# alb32r003x register map
Vendor: ALB; Series: ALB RT SoC
CPU: ALB XF, little endian
Registers are 32-bit, access not given, reset 0x0 unless marked. A register's access mark holds for its fields unless they carry their own. Offsets are from the block's base; [hi:lo] are bit positions; {n}, {i} and the like mark numbered series; 'fields as' and 'values as' point back to an identical list.

## EPWM1
Base 0x21000000
Same registers: EPWM2 0x21000400, EPWM3 0x21000800, EPWM4 0x21000C00, EPWM5 0x21001000, EPWM6 0x21001400, EPWM7 0x21001800, EPWM8 0x21001C00
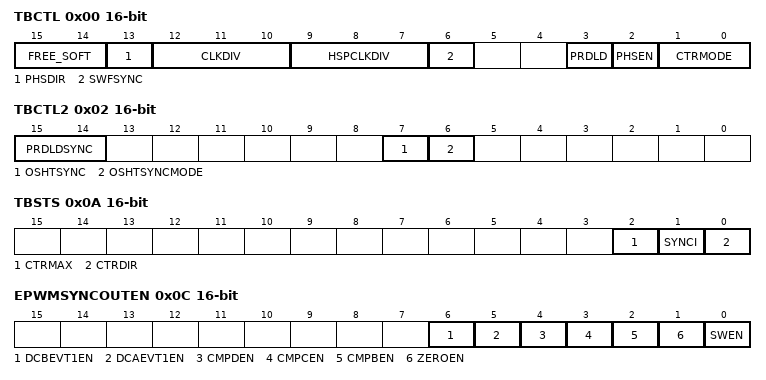
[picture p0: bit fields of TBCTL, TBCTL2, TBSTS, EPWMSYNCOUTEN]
0x00 TBCTL 16-bit
  [15:14] FREE_SOFT — 该寄存器未使用
  [13] PHSDIR — Phase Direction Bit
  [12:10] CLKDIV — Time Base Clock Pre-Scale Bits
  [9:7] HSPCLKDIV — High Speed Time Base Clock Pre-Scale Bits
  [6] SWFSYNC — Software Forced Sync Pulse
  [3] PRDLD — Active Period Reg Load from Shadow Select
  [2] PHSEN — Counter Reg Load from Phase Reg Enable
  [1:0] CTRMODE — Counter Mode
0x02 TBCTL2 16-bit
  [15:14] PRDLDSYNC — Shadow to Active Period Register Load on SYNC event
  [7] OSHTSYNC — Oneshot sync bit
  [6] OSHTSYNCMODE — Oneshot sync enable bit
0x08 TBCTR 16-bit
  [15:0] TBCTR — Time Base Counter Register
0x0A TBSTS 16-bit
  [2] CTRMAX — Time-Base Counter Max Latched Status Bit
  [1] SYNCI — Input Synchronization Latched Status Bit
  [0] CTRDIR — Time Base Counter Direction Status Bit
0x0C EPWMSYNCOUTEN 16-bit
  [6] DCBEVT1EN — This bit enables the DCBEVT1.sync event to set the EPWMxSYNCO
  [5] DCAEVT1EN — This bit enables the DCAEVT1.sync event to set the
  [4] CMPDEN — This bit enables the TBCTR = CMPD
  [3] CMPCEN — This bit enables the TBCTR = CMPC
  [2] CMPBEN — This bit enables the TBCTR = CMPB event to set the
  [1] ZEROEN — This bit enables the TBCTR = 0x0000 event to set the
  [0] SWEN — This bit enables the TBCTL.SWFSYNC bit to set the EPWMxSYNCO
0x0E TBCTL3 16-bit
  [0] OSSFRCEN — This bit determines which bit sets the EPWMxSYNCOUT One Shot
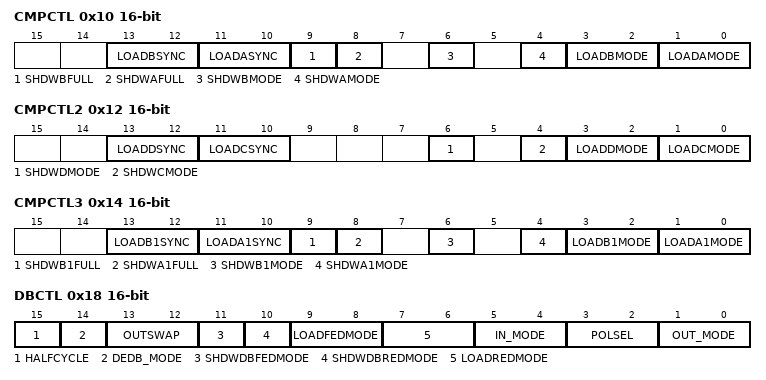
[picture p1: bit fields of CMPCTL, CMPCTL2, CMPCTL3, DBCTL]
0x10 CMPCTL 16-bit
  [13:12] LOADBSYNC — Shadow to Active CMPB Register Load on SYNC event
  [11:10] LOADASYNC — Shadow to Active CMPA Register Load on SYNC event
  [9] SHDWBFULL — Counter-compare B (CMPB) Shadow Register Full Status Flag
  [8] SHDWAFULL — Counter-compare A (CMPA) Shadow Register Full Status Flag
  [6] SHDWBMODE — Counter-compare B (CMPB) Register Operating Mode
  [4] SHDWAMODE — Counter-compare A (CMPA) Register Operating Mode
  [3:2] LOADBMODE — Active Counter-Compare B (CMPB) Load From Shadow Select
  [1:0] LOADAMODE — Active Counter-Compare A (CMPA) Load From Shadow Select Mode
0x12 CMPCTL2 16-bit
  [13:12] LOADDSYNC — Shadow to Active CMPD Register Load on SYNC event
  [11:10] LOADCSYNC — Shadow to Active CMPC Register Load on SYNC event
  [6] SHDWDMODE — Counter-Compare D Register Operating Mode
  [4] SHDWCMODE — Counter-Compare C Register Operating Mode
  [3:2] LOADDMODE — Active Counter-Compare D (CMPD) Load from Shadow Select Mode
  [1:0] LOADCMODE — Active Counter-Compare C (CMPC) Load from Shadow Select Mode
0x14 CMPCTL3 16-bit
  [13:12] LOADB1SYNC — Shadow to Active CMPB1 Register Load on SYNC event
  [11:10] LOADA1SYNC — Shadow to Active CMPA1 Register Load on SYNC event
  [9] SHDWB1FULL — Counter-compare B1 (CMPB1) Shadow Register Full Status Flag
  [8] SHDWA1FULL — Counter-compare A1 (CMPA1) Shadow Register Full Status Flag
  [6] SHDWB1MODE — Counter-compare B1 (CMPB1) Register Operating Mode
  [4] SHDWA1MODE — Counter-compare A1 (CMPA1) Register Operating Mode
  [3:2] LOADB1MODE — Active Counter-Compare B1 (CMPB1) Load From Shadow Select
  [1:0] LOADA1MODE — Active Counter-Compare A1 (CMPA1) Load From Shadow Select Mode
0x18 DBCTL 16-bit
  [15] HALFCYCLE — 该寄存器未使用
  [14] DEDB_MODE — Dead Band Dual-Edge B Mode Control (S8 switch)
  [13:12] OUTSWAP — Dead Band Output Swap Control
  [11] SHDWDBFEDMODE — FED Dead-Band Load Mode
  [10] SHDWDBREDMODE — RED Dead-Band Load Mode
  [9:8] LOADFEDMODE — Active DBFED Load from Shadow Select Mode
  [7:6] LOADREDMODE — Active DBRED Load from Shadow Select Mode
  [5:4] IN_MODE — Dead-Band Input Mode Control
  [3:2] POLSEL — Polarity Select Control
  [1:0] OUT_MODE — Dead-Band Output Mode Control
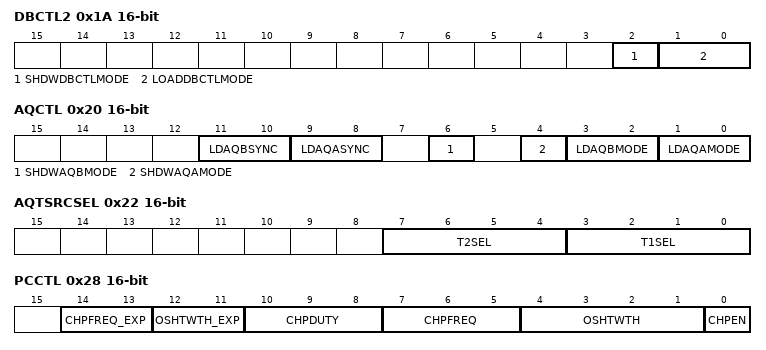
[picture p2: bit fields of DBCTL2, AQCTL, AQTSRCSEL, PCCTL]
0x1A DBCTL2 16-bit
  [2] SHDWDBCTLMODE — DBCTL Load Mode
  [1:0] LOADDBCTLMODE — Active DBCTL Load from Shadow Select Mode
0x20 AQCTL 16-bit
  [11:10] LDAQBSYNC — Shadow to Active AQCTLB Register Load on SYNC event
  [9:8] LDAQASYNC — Shadow to Active AQCTLA Register Load on SYNC event
  [6] SHDWAQBMODE — Action Qualifier B Register operating mode
  [4] SHDWAQAMODE — Action Qualifier A Register operating mode
  [3:2] LDAQBMODE — Active Action Qualifier B Load from Shadow Select Mode
  [1:0] LDAQAMODE — Active Action Qualifier A Load from Shadow Select Mode
0x22 AQTSRCSEL 16-bit
  [7:4] T2SEL — T2 Event Source Select Bits
  [3:0] T1SEL — T1 Event Source Select Bits
0x28 PCCTL 16-bit
  [14:13] CHPFREQ_EXP — Chopping Clock Frequency EXP
  [12:11] OSHTWTH_EXP — One-Shot Pulse Width EXP
  [10:8] CHPDUTY — Chopping Clock Duty Cycle
  [7:5] CHPFREQ — Chopping Clock Frequency
  [4:1] OSHTWTH — One-Shot Pulse Width
  [0] CHPEN — PWM-Chopping Enable
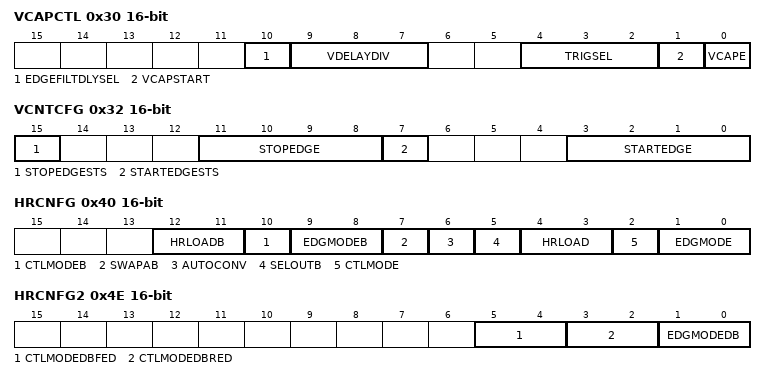
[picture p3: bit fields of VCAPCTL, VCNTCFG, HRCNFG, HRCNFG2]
0x30 VCAPCTL 16-bit
  [10] EDGEFILTDLYSEL — Valley Switching Mode Delay Selection
  [9:7] VDELAYDIV — Valley Delay Mode Divide Enable
  [4:2] TRIGSEL — Status of Numbered of Captured Events
  [1] VCAPSTART — Valley Capture Start
  [0] VCAPE — Valley Capture Enable/Disable
0x32 VCNTCFG 16-bit
  [15] STOPEDGESTS — Stop Edge Status Bit
  [11:8] STOPEDGE — Counter Stop Edge Selection
  [7] STARTEDGESTS — Start Edge Status Bit
  [3:0] STARTEDGE — Counter Start Edge Selection
0x40 HRCNFG 16-bit
  [12:11] HRLOADB — Shadow Mode Bit
  [10] CTLMODEB — 该寄存器未使用
  [9:8] EDGMODEB — 该寄存器未使用
  [7] SWAPAB — 该寄存器未使用
  [6] AUTOCONV — 该寄存器未使用
  [5] SELOUTB — 该寄存器未使用
  [4:3] HRLOAD — Shadow Mode Bit
  [2] CTLMODE — 该寄存器未使用
  [1:0] EDGMODE — 该寄存器未使用
0x42 HRPWR 16-bit
  [15] CALPWRON — 该寄存器未使用
0x4C HRMSTEP 16-bit
  [7:0] HRMSTEP — 该寄存器未使用
0x4E HRCNFG2 16-bit
  [5:4] CTLMODEDBFED — Shadow Mode Bit - selection should match
  [3:2] CTLMODEDBRED — Shadow Mode Bit - selection should match
  [1:0] EDGMODEDB — 该寄存器未使用
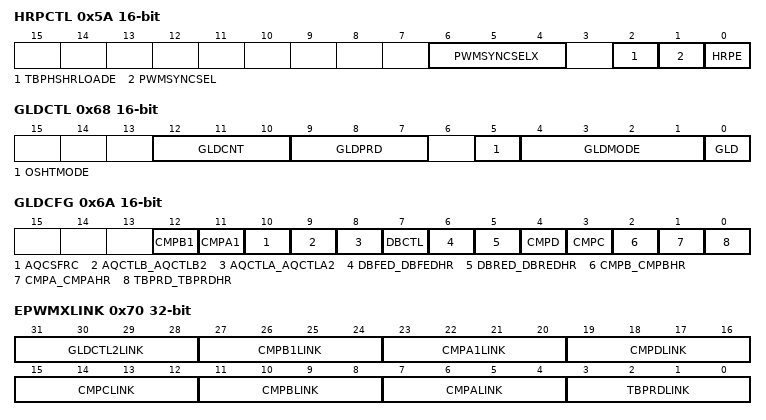
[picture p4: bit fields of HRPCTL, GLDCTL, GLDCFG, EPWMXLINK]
0x5A HRPCTL 16-bit
  [6:4] PWMSYNCSELX — Extended selection bits for EPWMSYNCPER
  [2] TBPHSHRLOADE — TBPHSHR Load Enable
  [1] PWMSYNCSEL — PWMSYNC Source Select Bit: This bit selects the source for the
  [0] HRPE — 该寄存器未使用
0x5C TRREM 16-bit
  [10:0] TRREM — 该寄存器未使用
0x68 GLDCTL 16-bit
  [12:10] GLDCNT — Global Load Strobe Counter Register
  [9:7] GLDPRD — Global Load Strobe Period Select Register
  [5] OSHTMODE — One Shot Load Mode Control Bit
  [4:1] GLDMODE — Global Load Pulse selection for Shadow to Active Mode Reloads
  [0] GLD — Global Shadow to Active Load Event Control
0x6A GLDCFG 16-bit
  [12] CMPB1 — CMPB1 Link Bits
  [11] CMPA1 — CMPA1 Link Bits
  [10] AQCSFRC — Global load event configuration for AQCSFRC
  [9] AQCTLB_AQCTLB2 — Global load event configuration for AQCTLB AQCTLB2
  [8] AQCTLA_AQCTLA2 — Global load event configuration for AQCTLA AQCTLA2
  [7] DBCTL — Global load event configuration for DBCTL
  [6] DBFED_DBFEDHR — Global load event configuration for DBFED DBFEDHR
  [5] DBRED_DBREDHR — Global load event configuration for DBRED DBREDHR
  [4] CMPD — Global load event configuration for CMPD
  [3] CMPC — Global load event configuration for CMPC
  [2] CMPB_CMPBHR — Global load event configuration for CMPB CMPBHR
  [1] CMPA_CMPAHR — Global load event configuration for CMPA CMPAHR
  [0] TBPRD_TBPRDHR — Global load event configuration for TBPRD TBPRDHR
0x70 EPWMXLINK
  [31:28] GLDCTL2LINK — GLDCTL2 Link Bits
  [27:24] CMPB1LINK — CMPB1 Link Bits
  [23:20] CMPA1LINK — CMPA1 Link Bits
  [19:16] CMPDLINK — CMPD Link Bits
  [15:12] CMPCLINK — CMPC Link Bits
  [11:8] CMPBLINK — CMPB CMPBHR Link Bits
  [7:4] CMPALINK — CMPA CMPAHR Link Bits
  [3:0] TBPRDLINK — TBPRD TBPRDHR Link Bits
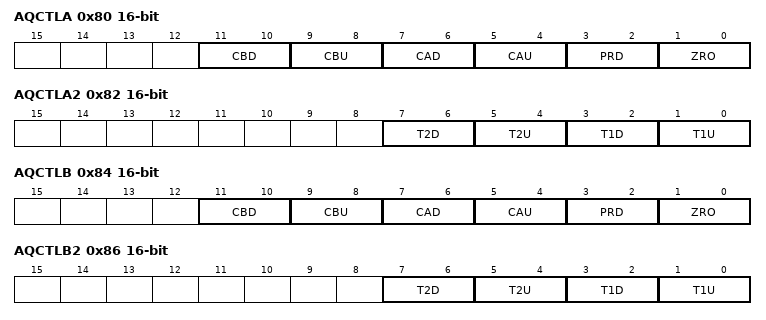
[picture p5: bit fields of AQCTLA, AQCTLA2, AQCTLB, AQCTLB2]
0x80 AQCTLA 16-bit
  [11:10] CBD — Action When TBCTR = CMPB on Down Count
  [9:8] CBU — Action When TBCTR = CMPB on Up Count
  [7:6] CAD — Action When TBCTR = CMPA on Down Count
  [5:4] CAU — Action When TBCTR = CMPA on Up Count
  [3:2] PRD — Action When TBCTR = TBPRD
  [1:0] ZRO — Action When TBCTR = 0
0x82 AQCTLA2 16-bit
  [7:6] T2D — Action when event occurs on T2 in DOWN-Count
  [5:4] T2U — Action when event occurs on T2 in UP-Count
  [3:2] T1D — Action when event occurs on T1 in DOWN-Count
  [1:0] T1U — Action when event occurs on T1 in UP-Count
0x84 AQCTLB 16-bit
  fields as AQCTLA
0x86 AQCTLB2 16-bit
  fields as AQCTLA2
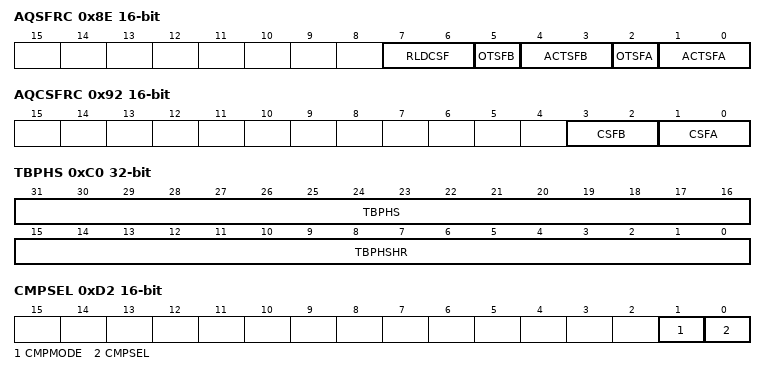
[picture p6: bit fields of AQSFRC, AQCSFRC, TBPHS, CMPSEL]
0x8E AQSFRC 16-bit
  [7:6] RLDCSF — AQCSFRC Active Register Reload From Shadow Options
  [5] OTSFB — One-Time Software Forced Event on Output B
  [4:3] ACTSFB — Action When One-Time Software Force B is Invoked
  [2] OTSFA — One-Time Software Forced Event on Output A
  [1:0] ACTSFA — Action When One-Time Software Force A ls Invoked
0x92 AQCSFRC 16-bit
  [3:2] CSFB — Continuous Software Force on Output B
  [1:0] CSFA — Continuous Software Force on Output A
0xA0 DBREDHR 16-bit
  [15:9] DBREDHR — Dead Band Rising Edge Delay High Resolution Bits
0xA2 DBRED 16-bit
  [13:0] DBRED — Rising edge delay value
0xA4 DBFEDHR 16-bit
  [15:9] DBFEDHR — Dead Band Falling Edge Delay High Resolution Bits
0xA6 DBFED 16-bit
  [13:0] DBFED — Falling Edge Delay Count
0xC0 TBPHS
  [31:16] TBPHS — Phase Offset Register
  [15:0] TBPHSHR — Phase Offset (High Resolution) Register.
0xC4 TBPRDHR 16-bit
  [15:0] TBPRDHR — Period High Resolution Bits
0xC6 TBPRD 16-bit
  [15:0] TBPRD — Time Base Period Registe
0xCA CMPA1 16-bit
  [15:0] CMPA1 — Compare A1 Register
0xCE CMPB1 16-bit
  [15:0] CMPB1 — Compare B1 Register
0xD2 CMPSEL 16-bit
  [1] CMPMODE — Cmpa/b/a1/b1/c/d implementation configuration register
  [0] CMPSEL — The ePWMB AQ module uses the cmpa/b select configuration register
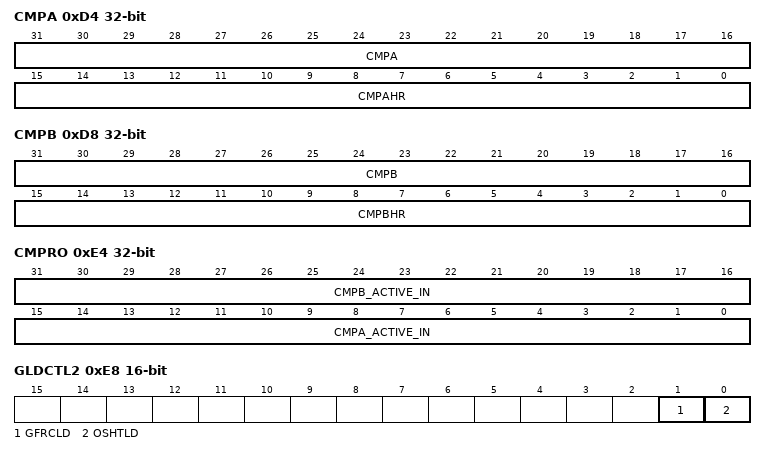
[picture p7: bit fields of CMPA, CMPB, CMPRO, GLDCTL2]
0xD4 CMPA
  [31:16] CMPA — Compare A Register
  [15:0] CMPAHR — Compare A HRPWM Extension Register
0xD8 CMPB
  [31:16] CMPB — Compare B Register
  [15:0] CMPBHR — Compare B High Resolution Bits
0xDE CMPC 16-bit
  [15:0] CMPC — Compare C Register
0xE2 CMPD 16-bit
  [15:0] CMPD — Compare D Register
0xE4 CMPRO
  [31:16] CMPB_ACTIVE_IN — CMPB上报寄存器
  [15:0] CMPA_ACTIVE_IN — CMPA上报寄存器
0xE8 GLDCTL2 16-bit
  [1] GFRCLD — Force Load Event in One Shot Mode
  [0] OSHTLD — Enable Reload Event in One Shot Mode
0xEE SWVDELVAL 16-bit
  [15:0] SWVDELVAL — Software Valley Delay Value Register
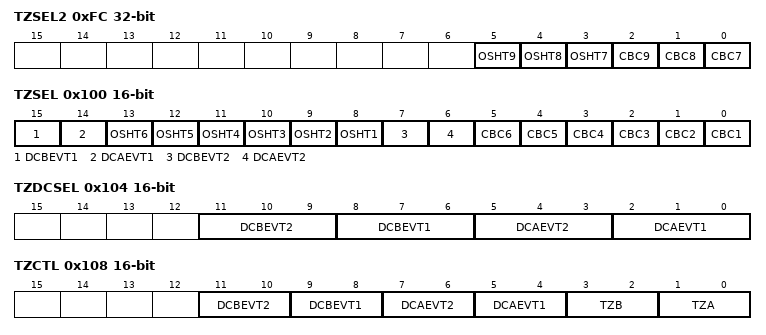
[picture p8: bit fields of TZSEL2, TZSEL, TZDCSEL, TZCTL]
0xFC TZSEL2
  [5] OSHT9 — Trip-zone 9 (TZ9) Select
  [4] OSHT8 — Trip-zone 8 (TZ8) Select
  [3] OSHT7 — Trip-zone 7 (TZ7) Select
  [2] CBC9 — Trip-zone 9 (TZ9) Select
  [1] CBC8 — Trip-zone 8 (TZ8) Select
  [0] CBC7 — Trip-zone 7 (TZ7) Select
0x100 TZSEL 16-bit
  [15] DCBEVT1 — Digital Compare Output B Event 1 Select
  [14] DCAEVT1 — Digital Compare Output A Event 1 Select
  [n+7] OSHT{n} (n=1..6) — Trip-zone {n} (TZ{n}) Select
  [7] DCBEVT2 — Digital Compare Output B Event 2 Select
  [6] DCAEVT2 — Digital Compare Output A Event 2 Select
  [n-1] CBC{n} (n=1..6) — Trip-zone {n} (TZ{n}) Select
0x104 TZDCSEL 16-bit
  [11:9] DCBEVT2 — Digital Compare Output B Event 2 Selection
  [8:6] DCBEVT1 — Digital Compare Output B Event 1 Selection
  [5:3] DCAEVT2 — Digital Compare Output A Event 2 Selection
  [2:0] DCAEVT1 — Digital Compare Output A Event 1 Selection
0x108 TZCTL 16-bit
  [11:10] DCBEVT2 — Digital Compare Output B Event 2 Action On EPWMxB
  [9:8] DCBEVT1 — Digital Compare Output B Event 1 Action On EPWMxB
  [7:6] DCAEVT2 — Digital Compare Output A Event 2 Action On EPWMxA
  [5:4] DCAEVT1 — Digital Compare Output A Event 1 Action On EPWMxA
  [3:2] TZB — TZ1 to TZ6, DCAEVT1/2, DCBEVT1/2Trip Action On EPWMxB
  [1:0] TZA — TZ1 to TZ6, DCAEVT1/2, DCBEVT1/2 Trip Action On EPWMxA
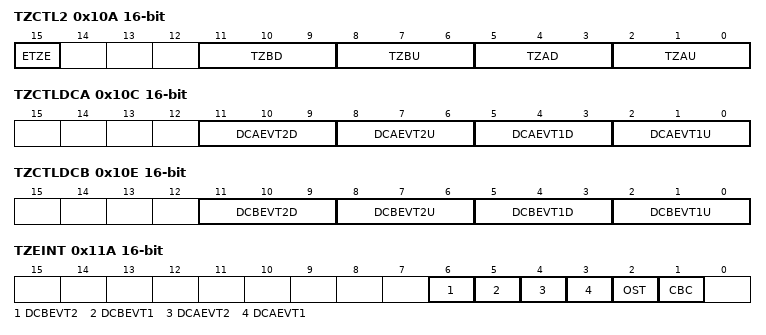
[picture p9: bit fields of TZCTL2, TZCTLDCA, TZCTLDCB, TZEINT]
0x10A TZCTL2 16-bit
  [15] ETZE — TZCTL2 Enable
  [11:9] TZBD — TZ1 to TZ6 Trip Action On EPWMxB while Count direction is DOWN
  [8:6] TZBU — TZ1 to TZ6, DCAEVT1/2, DCBEVT1/2 Trip Action On EPWMxB
  [5:3] TZAD — TZ1 to TZ6, DCAEVT1/2, DCBEVT1/2 Trip Action On EPWMxA
  [2:0] TZAU — TZ1 to TZ6, DCAEVT1/2, DCBEVT1/2 Trip Action On EPWMxA
0x10C TZCTLDCA 16-bit
  [11:9] DCAEVT2D — Digital Compare Output A Event 2 Action On EPWMxA while Count
  [8:6] DCAEVT2U — Digital Compare Output A Event 2 Action On EPWMxA while Count
  [5:3] DCAEVT1D — Digital Compare Output A Event 1 Action On EPWMxA while Count
  [2:0] DCAEVT1U — Digital Compare Output A Event 1 Action On EPWMxA while Count
0x10E TZCTLDCB 16-bit
  [11:9] DCBEVT2D — Digital Compare Output B Event 2 Action On EPWMxB while Count
  [8:6] DCBEVT2U — Digital Compare Output B Event 2 Action On EPWMxB while Count
  [5:3] DCBEVT1D — Digital Compare Output B Event 1 Action On EPWMxB while Count
  [2:0] DCBEVT1U — Digital Compare Output B Event 1 Action On EPWMxB while Count
0x11A TZEINT 16-bit
  [6] DCBEVT2 — Digital Compare Output B Event 2 Interrupt Enable
  [5] DCBEVT1 — Digital Compare Output B Event 1 Interrupt Enable
  [4] DCAEVT2 — Digital Compare Output A Event 2 Interrupt Enable
  [3] DCAEVT1 — Digital Compare Output A Event 1 Interrupt Enable
  [2] OST — Trip-zone One-Shot Interrupt Enable
  [1] CBC — Trip-zone Cycle-by-Cycle Interrupt Enable
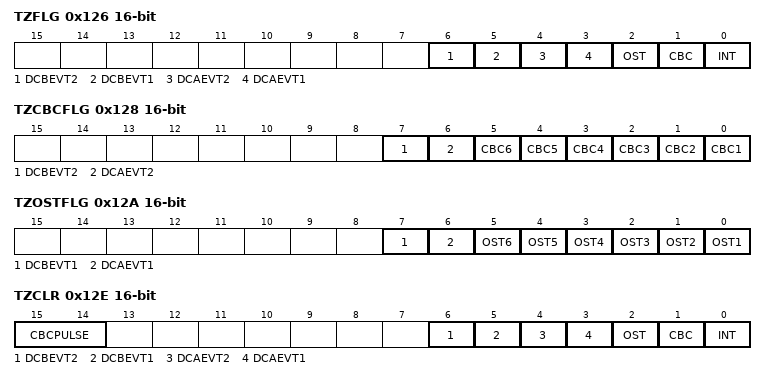
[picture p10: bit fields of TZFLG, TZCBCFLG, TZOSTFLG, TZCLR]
0x126 TZFLG 16-bit
  [6] DCBEVT2 — Latched Status Flag for Digital Compare Output B Event 2
  [5] DCBEVT1 — Latched Status Flag for Digital Compare Output B Event 1
  [4] DCAEVT2 — Latched Status Flag for Digital Compare Output A Event 2
  [3] DCAEVT1 — Latched Status Flag for Digital Compare Output A Event 1
  [2] OST — Latched Status Flag for A One-Shot Trip Event
  [1] CBC — Latched Status Flag for Cycle-By-Cycle Trip Event
  [0] INT — Latched Trip Interrupt Status Flag
0x128 TZCBCFLG 16-bit
  [7] DCBEVT2 — Latched Status Flag for Digital Compare B Output Event 2 Trip Latch
  [6] DCAEVT2 — Latched Status Flag for Digital Compare A Output Event 2 Trip Latch
  [n-1] CBC{n} (n=1..6) — Latched Status Flag for CBC{n} Trip Latch
0x12A TZOSTFLG 16-bit
  [7] DCBEVT1 — Latched Status Flag for Digital Compare B Output Event 1 Trip Latch
  [6] DCAEVT1 — Latched Status Flag for Digital Compare A Output Event 1 Trip Latch
  [n-1] OST{n} (n=1..6) — Latched Status Flag for OST{n} Trip Latch
0x12E TZCLR 16-bit
  [15:14] CBCPULSE — Clear Pulse for Cycle-By-Cycle (CBC) Trip Latch
  [6] DCBEVT2 — Clear Flag for Digital Compare Output B Event 2
  [5] DCBEVT1 — Clear Flag for Digital Compare Output B Event 1
  [4] DCAEVT2 — Clear Flag for Digital Compare Output A Event 2
  [3] DCAEVT1 — Clear Flag for Digital Compare Output A Event 1
  [2] OST — Clear Flag for One-Shot Trip (OST) Latch
  [1] CBC — Clear Flag for Cycle-By-Cycle (CBC) Trip Latch
  [0] INT — Global Interrupt Clear Flag
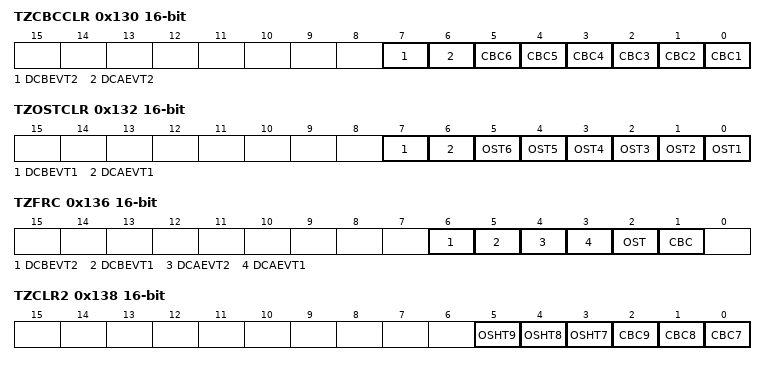
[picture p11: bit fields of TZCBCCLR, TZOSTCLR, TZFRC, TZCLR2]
0x130 TZCBCCLR 16-bit
  [7] DCBEVT2 — Clear Flag for Digital Compare Output B Event 2 selected for CBC
  [6] DCAEVT2 — Clear Flag for Digital Compare Output A Event 2 selected for CBC
  [n-1] CBC{n} (n=1..6) — Clear Flag for Cycle-By-Cycle (CBC{n}) Trip Latch
0x132 TZOSTCLR 16-bit
  [7] DCBEVT1 — Clear Flag for Digital Compare Output B Event 1 selected for OST
  [6] DCAEVT1 — Clear Flag for Digital Compare Output A Event 1 selected for OST
  [n-1] OST{n} (n=1..6) — Clear Flag for Oneshot (OST{n}) Trip Latch
0x136 TZFRC 16-bit
  [6] DCBEVT2 — Force Flag for Digital Compare Output B Event 2
  [5] DCBEVT1 — Force Flag for Digital Compare Output B Event 1
  [4] DCAEVT2 — Force Flag for Digital Compare Output A Event 2
  [3] DCAEVT1 — Force Flag for Digital Compare
  [2] OST — Force a One-Shot Trip Event via Software
  [1] CBC — Force a Cycle-by-Cycle Trip Event via Software
0x138 TZCLR2 16-bit
  [5] OSHT9 — Clear Flag for Oneshot (OST9) Trip Latch
  [4] OSHT8 — Clear Flag for Oneshot (OST8) Trip Latch
  [3] OSHT7 — Clear Flag for Oneshot (OST7) Trip Latch
  [2] CBC9 — Clear Flag for Cycle-By-Cycle (CBC9) Trip Latch
  [1] CBC8 — Clear Flag for Cycle-By-Cycle (CBC8) Trip Latch
  [0] CBC7 — Clear Flag for Cycle-By-Cycle (CBC7) Trip Latch
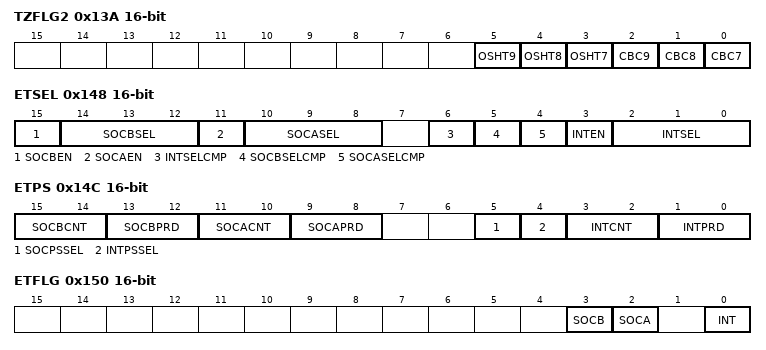
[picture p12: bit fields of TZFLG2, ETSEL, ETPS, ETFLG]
0x13A TZFLG2 16-bit
  [5] OSHT9 — Latched Status Flag for OST9 Trip Latch
  [4] OSHT8 — Latched Status Flag for OST8 Trip Latch
  [3] OSHT7 — Latched Status Flag for OST7 Trip Latch
  [2] CBC9 — Latched Status Flag for CBC9 Trip Latch
  [1] CBC8 — Latched Status Flag for CBC8 Trip Latch
  [0] CBC7 — Latched Status Flag for CBC7 Trip Latch
0x148 ETSEL 16-bit
  [15] SOCBEN — Enable the ADC Start of Conversion B (EPWMxSOCB) Pulse
  [14:12] SOCBSEL — EPWMxSOCB Selection Options
  [11] SOCAEN — Enable the ADC Start of Conversion A (EPWMxSOCA) Pulse
  [10:8] SOCASEL — EPWMxSOCA Selection Options
  [6] INTSELCMP — EPWMxINT Compare Register Selection Options
  [5] SOCBSELCMP — EPWMxSOCB Compare Register Selection Options
  [4] SOCASELCMP — EPWMxSOCA Compare Register Selection Options
  [3] INTEN — Enable ePWM Interrupt (EPWMx INT) Generation
  [2:0] INTSEL — ePWM Interrupt (EPWMx INT) Selection Options
0x14C ETPS 16-bit
  [15:14] SOCBCNT — ePWM ADC Start-of-Conversion B Event (EPWMxSOCB) Counter
  [13:12] SOCBPRD — ePWM ADC Start-of-Conversion B Event (EPWMxSOCB) Period
  [11:10] SOCACNT — ePWM ADC Start-of-Conversion A Event (EPWMxSOCA) Counter
  [9:8] SOCAPRD — ePWM ADC Start-of-Conversion A Event (EPWMxSOCA) Period
  [5] SOCPSSEL — EPWMxSOC A/B Pre-Scale Selection Bits
  [4] INTPSSEL — EPWMxINTn Pre-Scale Selection Bits
  [3:2] INTCNT — ePWM Interrupt Event (EPWMx INT) Counter Register
  [1:0] INTPRD — ePWM Interrupt (EPWMx INT) Period Select
0x150 ETFLG 16-bit
  [3] SOCB — Latched ePWM ADC Start-of-Conversion A (EPWMxSOCB) Status
  [2] SOCA — Latched ePWM ADC Start-of-Conversion A (EPWMxSOCA) Status
  [0] INT — Latched ePWM Interrupt (EPWMx INT) Status Flag
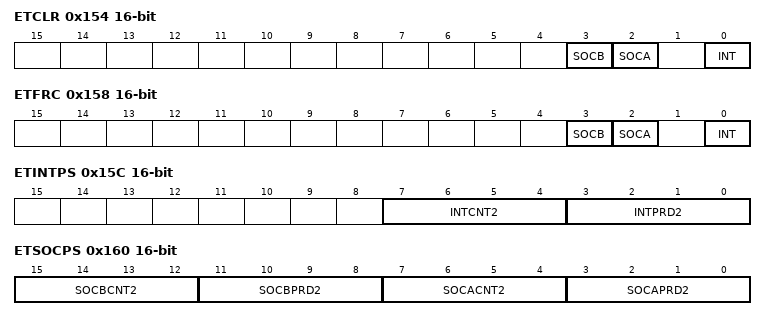
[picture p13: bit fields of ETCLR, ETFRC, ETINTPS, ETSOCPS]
0x154 ETCLR 16-bit
  [3] SOCB — ePWM ADC Start-of-Conversion A (EPWMxSOCB) Flag Clear Bit
  [2] SOCA — ePWM ADC Start-of-Conversion A (EPWMxSOCA) Flag Clear Bit
  [0] INT — ePWM Interrupt (EPWMx INT) Flag Clear Bit
0x158 ETFRC 16-bit
  [3] SOCB — SOCB Force Bit
  [2] SOCA — SOCA Force Bit
  [0] INT — INT Force Bit
0x15C ETINTPS 16-bit
  [7:4] INTCNT2 — EPWMxINT Counter 2
  [3:0] INTPRD2 — EPWMxINT Period 2 Select
0x160 ETSOCPS 16-bit
  [15:12] SOCBCNT2 — EPWMxSOCB Counter 2
  [11:8] SOCBPRD2 — EPWMxSOCB Period 2 Select
  [7:4] SOCACNT2 — EPWMxSOCA Counter 2
  [3:0] SOCAPRD2 — EPWMxSOCA Period 2 Select
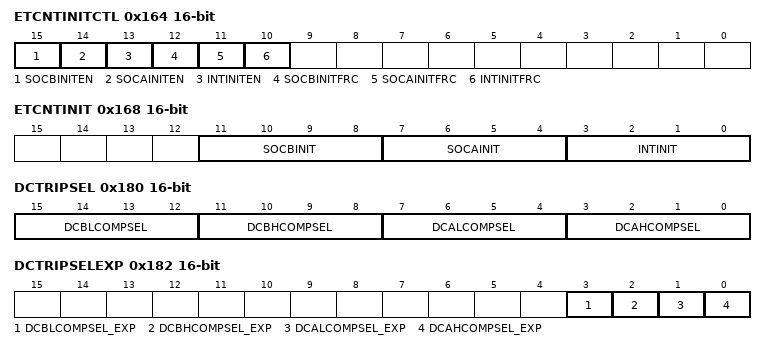
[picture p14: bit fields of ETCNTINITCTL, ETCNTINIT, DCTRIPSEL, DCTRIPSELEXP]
0x164 ETCNTINITCTL 16-bit
  [15] SOCBINITEN — EPWMxSOCB Counter 2 Initialization Enable
  [14] SOCAINITEN — EPWMxSOCA Counter 2 Initialization Enable
  [13] INTINITEN — EPWMxINT Counter 2 Initialization Enable
  [12] SOCBINITFRC — EPWMxSOCB Counter 2 Initialization Force
  [11] SOCAINITFRC — EPWMxSOCA Counter 2 Initialization Force
  [10] INTINITFRC — EPWMxINT Counter 2 Initialization Force
0x168 ETCNTINIT 16-bit
  [11:8] SOCBINIT — EPWMxSOCB Counter 2 Initialization Bits
  [7:4] SOCAINIT — EPWMxSOCA Counter 2 Initialization Bits
  [3:0] INTINIT — EPWMxINT Counter 2 Initialization Bits
0x180 DCTRIPSEL 16-bit
  [15:12] DCBLCOMPSEL — Digital Compare B Low Input Select Bits
  [11:8] DCBHCOMPSEL — Digital Compare B High Input Select Bits
  [7:4] DCALCOMPSEL — Digital Compare A Low Input Select Bits
  [3:0] DCAHCOMPSEL — Digital Compare A High Input Select Bits
0x182 DCTRIPSELEXP 16-bit
  [3] DCBLCOMPSEL_EXP — Digital Compare B Low Input Select Bits Exp
  [2] DCBHCOMPSEL_EXP — Digital Compare B High Input Select Bits Exp
  [1] DCALCOMPSEL_EXP — Digital Compare A Low Input Select Bits Exp
  [0] DCAHCOMPSEL_EXP — Digital Compare A High Input Select Bits Exp
0x186 DCACTL 16-bit
  [15] EVT2LAT — Indicates the status of DCAEVT2LAT signal.
  [14:13] EVT2LATCLRSEL — DCAEVT2 Latched clear source select:
  [12] EVT2LATSEL — DCAEVT2 Latched signal select:
  [9] EVT2FRCSYNCSEL — DCAEVT2 Force Synchronization Signal Select
  [8] EVT2SRCSEL — DCAEVT2 Source Signal Select
  [7] EVT1LAT — Indicates the status of DCAEVT1LAT signal.
  [6:5] EVT1LATCLRSEL — DCAEVT1 Latched clear source select:
  [4] EVT1LATSEL — DCAEVT1 Latched signal select:
  [3] EVT1SYNCE — DCAEVT1 SYNC,Enable/Disable
  [2] EVT1SOCE — DCAEVT1 SOC, Enable/Disable
  [1] EVT1FRCSYNCSEL — DCAEVT1 Force Synchronization Signal Select
  [0] EVT1SRCSEL — DCAEVT1 Source Signal Select
0x188 DCBCTL 16-bit
  [15] EVT2LAT — Indicates the status of DCBEVT2LAT signal.
  [14:13] EVT2LATCLRSEL — DCBEVT2 Latched clear source select:
  [12] EVT2LATSEL — DCBEVT2 Latched signal select
  [9] EVT2FRCSYNCSEL — DCBEVT2 Force Synchronization Signal Select
  [8] EVT2SRCSEL — DCBEVT2 Source Signal Select
  [7] EVT1LAT — Indicates the status of DCBEVT1LAT signal.
  [6:5] EVT1LATCLRSEL — DCBEVT1 Latched clear source select:
  [4] EVT1LATSEL — DCBEVT1 Latched signal select:
  [3] EVT1SYNCE — DCBEVT1 SYNC,Enable/Disable
  [2] EVT1SOCE — DCBEVT1 SOC, Enable/Disable
  [1] EVT1FRCSYNCSEL — DCBEVT1 Force Synchronization Signal Select
  [0] EVT1SRCSEL — DCBEVT1 Source Signal Select
0x18E DCFCTL 16-bit
  [15:13] EDGESTATUS
  [12:10] EDGECOUNT — Edge Count: These bits select how many edges to count before
  [9:8] EDGEMODE — Edge Mode Select:
  [6] EDGEFILTSEL — Edge Filter Select:
  [5:4] PULSESEL — Pulse Select For Blanking and Capture Alignment
  [3] BLANKINV — Blanking Window Inversion
  [2] BLANKE — Blanking Window Enable/Disable
  [1:0] SRCSEL — Filter Block Signal Source Select
0x190 DCCAPCTL 16-bit
  [15] CAPMODE — Counter Capture Mode
  [14] CAPCLR — DC Capture Latched Status Clear Flag
  [13] CAPSTS — Latched Status Flag for Capture Event
  [1] SHDWMODE — TBCTR Counter Capture Shadow Select Mode
  [0] CAPE — TBCTR Counter Capture Enable/Disable
0x192 DCFOFFSET 16-bit
  [15:0] DCFOFFSET — Blanking Window Offset
0x194 DCFOFFSETCNT 16-bit
  [15:0] DCFOFFSETCNT — Blanking Offset Counter
0x196 DCFWINDOW 16-bit
  [15:0] DCFWINDOW — Blanking Window Width
0x198 DCFWINDOWCNT 16-bit
  [15:0] DCFWINDOWCNT — Blanking Window Counter
0x19A BLANKPULSEMIXSEL 16-bit
  [9] CDD — Enable event time-base counter equal to CMPD when the timer is
  [8] CDU — Enable event time-base counter equal to CMPD when the timer is
  [7] CCD — Enable event time-base counter equal to CMPC when the timer is
  [6] CCU — Enable event time-base counter equal to CMPC when the timer is
  [5] CBD — Enable event time-base counter equal to CMPB when the timer is
  [4] CBU — Enable event time-base counter equal to CMPB when the
  [3] CAD — Enable event time-base counter equal to CMPA when the timer is
  [2] CAU — Enable event time-base counter equal to CMPA when the timer is
  [1] PRD — Enable event time-base counter equal to period (TBCTR = TBPRD)
  [0] ZRO — Enable event time-base counter equal to zero (TBCTR = 0x00) to the
0x19E DCCAP 16-bit
  [15:0] DCCAP — Digital Compare Time-Base Counter Capture
0x1A4 DCAHTRIPSEL 16-bit
  [14] TRIPINPUT15, [13] TRIPINPUT14, [n-1] TRIPINPUT{n} (n=1..12)
0x1A6 DCALTRIPSEL 16-bit
  [14] TRIPINPUT15, [13] TRIPINPUT14, [n-1] TRIPINPUT{n} (n=1..12)
0x1A8 DCBHTRIPSEL 16-bit
  [14] TRIPINPUT15, [13] TRIPINPUT14, [n-1] TRIPINPUT{n} (n=1..12)
0x1AA DCBLTRIPSEL 16-bit
  [14] TRIPINPUT15, [13] TRIPINPUT14, [n-1] TRIPINPUT{n} (n=1..12)
0x1AC DCTRIPSEL2 16-bit
  [11] TRIPINPUT18_DCBH — TRIP Input 18
  [10] TRIPINPUT17_DCBH — TRIP Input TZ8
  [9] TRIPINPUT16_DCBH — TRIP Input TZ7
  [8] TRIPINPUT18_DCBL — TRIP Input 18
  [7] TRIPINPUT17_DCBL — TRIP Input 17
  [6] TRIPINPUT16_DCBL — TRIP Input 16
  [5] TRIPINPUT18_DCAH — TRIP Input 18
  [4] TRIPINPUT17_DCAH — TRIP Input 17
  [3] TRIPINPUT16_DCAH — TRIP Input 16
  [2] TRIPINPUT18_DCAL — TRIP Input 18
  [1] TRIPINPUT17_DCAL — TRIP Input 17
  [0] TRIPINPUT16_DCAL — TRIP Input 16
0x1F4 EPWMLOCK
  [31:16] KEY — 该寄存器未使用
  [4] DCLOCK — 该寄存器未使用
  [3] TZCLRLOCK — 该寄存器未使用
  [2] TZCFGLOCK — 该寄存器未使用
  [1] GLLOCK — 该寄存器未使用
  [0] HRLOCK — 该寄存器未使用
0x1FA HWVDELVAL 16-bit
  [15:0] HWVDELVAL — Hardware Valley Delay Value Register
0x1FC VCNTVAL 16-bit
  [15:0] VCNTVAL — Valley Time Base Counter Register
